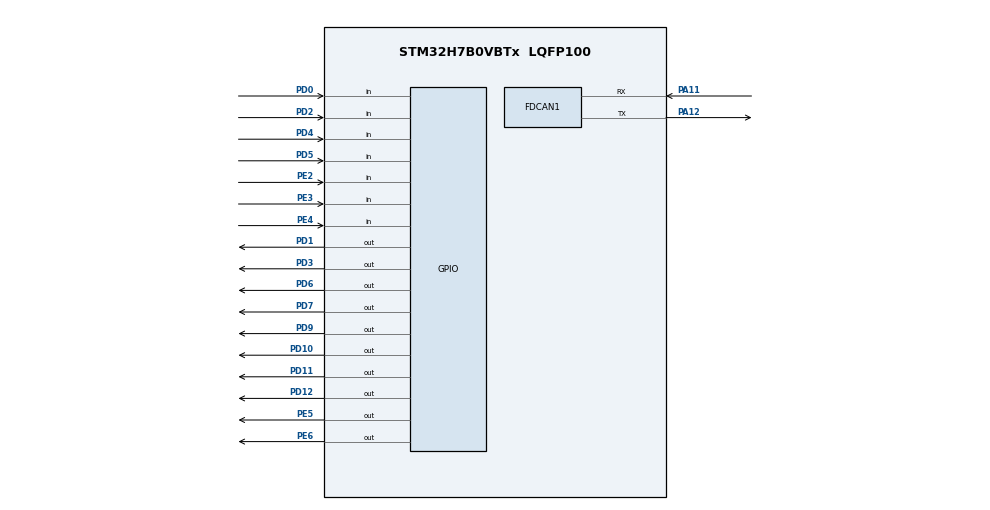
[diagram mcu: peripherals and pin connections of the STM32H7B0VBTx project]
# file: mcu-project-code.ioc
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FDCAN1.CalculateBaudRateNominal=533333
FDCAN1.CalculateTimeBitNominal=1875
FDCAN1.CalculateTimeQuantumNominal=375.0
Mcu.Family=STM32H7
Mcu.Name=STM32H7B0VBTx
Mcu.Package=LQFP100
NVIC.PriorityGroup=NVIC_PRIORITYGROUP_4
PA10.Signal=USART1_RX
PA11.Mode=FDCAN_Activate
PA11.Signal=FDCAN1_RX
PA12.Mode=FDCAN_Activate
PA12.Signal=FDCAN1_TX
PA13.Mode=JTAG_5_pins
PA13.Signal=DEBUG_JTMS-SWDIO
PA14.Mode=JTAG_5_pins
PA14.Signal=DEBUG_JTCK-SWCLK
PA15.Mode=JTAG_5_pins
PA15.Signal=DEBUG_JTDI
PA9.Signal=USART1_TX
PB13.Signal=SPI2_SCK
PB14.Signal=SPI2_MISO
PB15.Signal=SPI2_MOSI
PB3.Mode=JTAG_5_pins
PB3.Signal=DEBUG_JTDO-SWO
PB4.Mode=JTAG_5_pins
PB4.Signal=DEBUG_JTRST
PB6.Signal=I2C1_SCL
PB7.Signal=I2C1_SDA
PC10.Signal=USART3_TX
PC11.Signal=USART3_RX
PD0.Signal=GPIO_Input
PD1.Signal=GPIO_Output
PD10.Signal=GPIO_Output
PD11.Signal=GPIO_Output
PD12.Signal=GPIO_Output
PD2.Signal=GPIO_Input
PD3.Signal=GPIO_Output
PD4.Signal=GPIO_Input
PD5.Signal=GPIO_Input
PD6.Signal=GPIO_Output
PD7.Signal=GPIO_Output
PD9.Signal=GPIO_Output
PE2.Signal=GPIO_Input
PE3.Signal=GPIO_Input
PE4.Signal=GPIO_Input
PE5.Signal=GPIO_Output
PE6.Signal=GPIO_Output
ProjectManager.HeapSize=0x200
ProjectManager.StackSize=0x400
ProjectManager.TargetToolchain=STM32CubeIDE
RCC.ADCFreq_Value=129000000
RCC.APB1Freq_Value=32000000
RCC.APB2Freq_Value=32000000
RCC.APB3Freq_Value=32000000
RCC.APB4Freq_Value=32000000
RCC.CDPPRE=RCC_APB3_DIV2
RCC.CDPPRE1=RCC_APB1_DIV2
RCC.CDPPRE2=RCC_APB2_DIV2
RCC.CortexFreq_Value=64000000
RCC.DIVM1=4
RCC.DIVN1=8
RCC.DIVQ1=3
RCC.HCLKFreq_Value=64000000
RCC.PLLFRACN=0
RCC.SRDPPRE=RCC_APB4_DIV2
RCC.SYSCLKFreq_VALUE=64000000
RCC.USBFreq_Value=42666666.666666664
board=custom

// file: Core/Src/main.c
/* USER CODE BEGIN Header */
/**
  ******************************************************************************
  * @file           : main.c
  * @brief          : Main program body
  ******************************************************************************
  * @attention
  *
  * Copyright (c) 2026 STMicroelectronics.
  * All rights reserved.
  *
  * This software is licensed under terms that can be found in the LICENSE file
  * in the root directory of this software component.
  * If no LICENSE file comes with this software, it is provided AS-IS.
  *
  ******************************************************************************
  */
/* USER CODE END Header */
#include "main.h"

FDCAN_HandleTypeDef hfdcan1;

void SystemClock_Config(void);
static void MPU_Config(void);
static void MX_GPIO_Init(void);
static void MX_FDCAN1_Init(void);
static void UART_Init(void);
static void UART_Tx(void);
static void UART_Rx(void);

//CONOPS
static void Radio_Tx(int32_t data);
static int32_t Sensors_Rx(void);

int main(void)
{

  /* MPU Configuration--------------------------------------------------------*/
  MPU_Config();

  /* MCU Configuration--------------------------------------------------------*/

  /* Reset of all peripherals, Initializes the Flash interface and the Systick. */
  HAL_Init();

  /* Configure the system clock */
  SystemClock_Config();

  /* Initialize all configured peripherals */
  MX_GPIO_Init();
  MX_FDCAN1_Init();

  /* Infinite loop */
  /* USER CODE BEGIN WHILE */
  while (1)
  {

	  /*
	   * Wait for Sensors RX
	   * When Sensors Rx Radio Tx
	   * Win
	   */
    /* USER CODE END WHILE */
	  int32_t data = Sensors_Rx();
	  if (data) {
		  Radio_Tx(data);
	  } else {
		  continue;
	  }

  }
}

void SystemClock_Config(void)
{
  RCC_OscInitTypeDef RCC_OscInitStruct = {0};
  RCC_ClkInitTypeDef RCC_ClkInitStruct = {0};

  /*AXI clock gating */
  RCC->CKGAENR = 0xFFFFFFFF;

  /** Supply configuration update enable
  */
  HAL_PWREx_ConfigSupply(PWR_LDO_SUPPLY);

  /** Configure the main internal regulator output voltage
  */
  __HAL_PWR_VOLTAGESCALING_CONFIG(PWR_REGULATOR_VOLTAGE_SCALE3);

  while(!__HAL_PWR_GET_FLAG(PWR_FLAG_VOSRDY)) {}

  /** Initializes the RCC Oscillators according to the specified parameters
  * in the RCC_OscInitTypeDef structure.
  */
  RCC_OscInitStruct.OscillatorType = RCC_OSCILLATORTYPE_HSI;
  RCC_OscInitStruct.HSIState = RCC_HSI_DIV1;
  RCC_OscInitStruct.HSICalibrationValue = 64;
  RCC_OscInitStruct.PLL.PLLState = RCC_PLL_ON;
  RCC_OscInitStruct.PLL.PLLSource = RCC_PLLSOURCE_HSI;
  RCC_OscInitStruct.PLL.PLLM = 4;
  RCC_OscInitStruct.PLL.PLLN = 8;
  RCC_OscInitStruct.PLL.PLLP = 2;
  RCC_OscInitStruct.PLL.PLLQ = 3;
  RCC_OscInitStruct.PLL.PLLR = 2;
  RCC_OscInitStruct.PLL.PLLRGE = RCC_PLL1VCIRANGE_3;
  RCC_OscInitStruct.PLL.PLLVCOSEL = RCC_PLL1VCOWIDE;
  RCC_OscInitStruct.PLL.PLLFRACN = 0;
  if (HAL_RCC_OscConfig(&RCC_OscInitStruct) != HAL_OK)
  {
    Error_Handler();
  }

  /** Initializes the CPU, AHB and APB buses clocks
  */
  RCC_ClkInitStruct.ClockType = RCC_CLOCKTYPE_HCLK|RCC_CLOCKTYPE_SYSCLK
                              |RCC_CLOCKTYPE_PCLK1|RCC_CLOCKTYPE_PCLK2
                              |RCC_CLOCKTYPE_D3PCLK1|RCC_CLOCKTYPE_D1PCLK1;
  RCC_ClkInitStruct.SYSCLKSource = RCC_SYSCLKSOURCE_HSI;
  RCC_ClkInitStruct.SYSCLKDivider = RCC_SYSCLK_DIV1;
  RCC_ClkInitStruct.AHBCLKDivider = RCC_HCLK_DIV1;
  RCC_ClkInitStruct.APB3CLKDivider = RCC_APB3_DIV2;
  RCC_ClkInitStruct.APB1CLKDivider = RCC_APB1_DIV2;
  RCC_ClkInitStruct.APB2CLKDivider = RCC_APB2_DIV2;
  RCC_ClkInitStruct.APB4CLKDivider = RCC_APB4_DIV2;

  if (HAL_RCC_ClockConfig(&RCC_ClkInitStruct, FLASH_LATENCY_2) != HAL_OK)
  {
    Error_Handler();
  }
}

static void MX_FDCAN1_Init(void)
{

  hfdcan1.Instance = FDCAN1;
  hfdcan1.Init.FrameFormat = FDCAN_FRAME_CLASSIC;
  hfdcan1.Init.Mode = FDCAN_MODE_NORMAL;
  hfdcan1.Init.AutoRetransmission = DISABLE;
  hfdcan1.Init.TransmitPause = DISABLE;
  hfdcan1.Init.ProtocolException = DISABLE;
  hfdcan1.Init.NominalPrescaler = 16;
  hfdcan1.Init.NominalSyncJumpWidth = 1;
  hfdcan1.Init.NominalTimeSeg1 = 2;
  hfdcan1.Init.NominalTimeSeg2 = 2;
  hfdcan1.Init.DataPrescaler = 1;
  hfdcan1.Init.DataSyncJumpWidth = 1;
  hfdcan1.Init.DataTimeSeg1 = 1;
  hfdcan1.Init.DataTimeSeg2 = 1;
  hfdcan1.Init.MessageRAMOffset = 0;
  hfdcan1.Init.StdFiltersNbr = 0;
  hfdcan1.Init.ExtFiltersNbr = 0;
  hfdcan1.Init.RxFifo0ElmtsNbr = 0;
  hfdcan1.Init.RxFifo0ElmtSize = FDCAN_DATA_BYTES_8;
  hfdcan1.Init.RxFifo1ElmtsNbr = 0;
  hfdcan1.Init.RxFifo1ElmtSize = FDCAN_DATA_BYTES_8;
  hfdcan1.Init.RxBuffersNbr = 0;
  hfdcan1.Init.RxBufferSize = FDCAN_DATA_BYTES_8;
  hfdcan1.Init.TxEventsNbr = 0;
  hfdcan1.Init.TxBuffersNbr = 0;
  hfdcan1.Init.TxFifoQueueElmtsNbr = 0;
  hfdcan1.Init.TxFifoQueueMode = FDCAN_TX_FIFO_OPERATION;
  hfdcan1.Init.TxElmtSize = FDCAN_DATA_BYTES_8;
  if (HAL_FDCAN_Init(&hfdcan1) != HAL_OK)
  {
    Error_Handler();
  }

}

static void MX_GPIO_Init(void)
{
  GPIO_InitTypeDef GPIO_InitStruct = {0};

  /* GPIO Ports Clock Enable */
  __HAL_RCC_GPIOE_CLK_ENABLE();
  __HAL_RCC_GPIOB_CLK_ENABLE();
  __HAL_RCC_GPIOD_CLK_ENABLE();
  __HAL_RCC_GPIOA_CLK_ENABLE();
  __HAL_RCC_GPIOC_CLK_ENABLE();

  /*Configure GPIO pin Output Level */
  HAL_GPIO_WritePin(GPIOE, GPIO_PIN_5|GPIO_PIN_6, GPIO_PIN_RESET);

  /*Configure GPIO pin Output Level */
  HAL_GPIO_WritePin(GPIOD, GPIO_PIN_9|GPIO_PIN_10|GPIO_PIN_11|GPIO_PIN_12
                          |GPIO_PIN_1|GPIO_PIN_3|GPIO_PIN_6|GPIO_PIN_7, GPIO_PIN_RESET);

  /*Configure GPIO pins : PE2 PE3 PE4 */
  GPIO_InitStruct.Pin = GPIO_PIN_2|GPIO_PIN_3|GPIO_PIN_4;
  GPIO_InitStruct.Mode = GPIO_MODE_INPUT;
  GPIO_InitStruct.Pull = GPIO_NOPULL;
  HAL_GPIO_Init(GPIOE, &GPIO_InitStruct);

  /*Configure GPIO pins : PE5 PE6 */
  GPIO_InitStruct.Pin = GPIO_PIN_5|GPIO_PIN_6;
  GPIO_InitStruct.Mode = GPIO_MODE_OUTPUT_PP;
  GPIO_InitStruct.Pull = GPIO_NOPULL;
  GPIO_InitStruct.Speed = GPIO_SPEED_FREQ_LOW;
  HAL_GPIO_Init(GPIOE, &GPIO_InitStruct);

  /*Configure GPIO pins : PB13 PB14 PB15 */
  GPIO_InitStruct.Pin = GPIO_PIN_13|GPIO_PIN_14|GPIO_PIN_15;
  GPIO_InitStruct.Mode = GPIO_MODE_AF_PP;
  GPIO_InitStruct.Pull = GPIO_NOPULL;
  GPIO_InitStruct.Speed = GPIO_SPEED_FREQ_LOW;
  GPIO_InitStruct.Alternate = GPIO_AF5_SPI2;
  HAL_GPIO_Init(GPIOB, &GPIO_InitStruct);

  /*Configure GPIO pins : PD9 PD10 PD11 PD12
                           PD1 PD3 PD6 PD7 */
  GPIO_InitStruct.Pin = GPIO_PIN_9|GPIO_PIN_10|GPIO_PIN_11|GPIO_PIN_12
                          |GPIO_PIN_1|GPIO_PIN_3|GPIO_PIN_6|GPIO_PIN_7;
  GPIO_InitStruct.Mode = GPIO_MODE_OUTPUT_PP;
  GPIO_InitStruct.Pull = GPIO_NOPULL;
  GPIO_InitStruct.Speed = GPIO_SPEED_FREQ_LOW;
  HAL_GPIO_Init(GPIOD, &GPIO_InitStruct);

  /*Configure GPIO pins : PA9 PA10 */
  GPIO_InitStruct.Pin = GPIO_PIN_9|GPIO_PIN_10;
  GPIO_InitStruct.Mode = GPIO_MODE_AF_PP;
  GPIO_InitStruct.Pull = GPIO_NOPULL;
  GPIO_InitStruct.Speed = GPIO_SPEED_FREQ_LOW;
  GPIO_InitStruct.Alternate = GPIO_AF7_USART1;
  HAL_GPIO_Init(GPIOA, &GPIO_InitStruct);

  /*Configure GPIO pins : PC10 PC11 */
  GPIO_InitStruct.Pin = GPIO_PIN_10|GPIO_PIN_11;
  GPIO_InitStruct.Mode = GPIO_MODE_AF_PP;
  GPIO_InitStruct.Pull = GPIO_NOPULL;
  GPIO_InitStruct.Speed = GPIO_SPEED_FREQ_LOW;
  GPIO_InitStruct.Alternate = GPIO_AF7_USART3;
  HAL_GPIO_Init(GPIOC, &GPIO_InitStruct);

  /*Configure GPIO pins : PD0 PD2 PD4 PD5 */
  GPIO_InitStruct.Pin = GPIO_PIN_0|GPIO_PIN_2|GPIO_PIN_4|GPIO_PIN_5;
  GPIO_InitStruct.Mode = GPIO_MODE_INPUT;
  GPIO_InitStruct.Pull = GPIO_NOPULL;
  HAL_GPIO_Init(GPIOD, &GPIO_InitStruct);

  /*Configure GPIO pins : PB6 PB7 */
  GPIO_InitStruct.Pin = GPIO_PIN_6|GPIO_PIN_7;
  GPIO_InitStruct.Mode = GPIO_MODE_AF_OD;
  GPIO_InitStruct.Pull = GPIO_NOPULL;
  GPIO_InitStruct.Speed = GPIO_SPEED_FREQ_LOW;
  GPIO_InitStruct.Alternate = GPIO_AF4_I2C1;
  HAL_GPIO_Init(GPIOB, &GPIO_InitStruct);

}

/* MPU Configuration */

void MPU_Config(void)
{
  MPU_Region_InitTypeDef MPU_InitStruct = {0};

  /* Disables the MPU */
  HAL_MPU_Disable();

  /** Initializes and configures the Region and the memory to be protected
  */
  MPU_InitStruct.Enable = MPU_REGION_ENABLE;
  MPU_InitStruct.Number = MPU_REGION_NUMBER0;
  MPU_InitStruct.BaseAddress = 0x0;
  MPU_InitStruct.Size = MPU_REGION_SIZE_4GB;
  MPU_InitStruct.SubRegionDisable = 0x87;
  MPU_InitStruct.TypeExtField = MPU_TEX_LEVEL0;
  MPU_InitStruct.AccessPermission = MPU_REGION_NO_ACCESS;
  MPU_InitStruct.DisableExec = MPU_INSTRUCTION_ACCESS_DISABLE;
  MPU_InitStruct.IsShareable = MPU_ACCESS_SHAREABLE;
  MPU_InitStruct.IsCacheable = MPU_ACCESS_NOT_CACHEABLE;
  MPU_InitStruct.IsBufferable = MPU_ACCESS_NOT_BUFFERABLE;

  HAL_MPU_ConfigRegion(&MPU_InitStruct);
  /* Enables the MPU */
  HAL_MPU_Enable(MPU_PRIVILEGED_DEFAULT);

}

static void Radio_Tx(int32_t data){

}
static int32_t Sensors_Rx(void){
	return 0;
}

static void UART_Init(void){

}
static void UART_Tx(void){

}
static void UART_Rx(void){

}

void Error_Handler(void)
{
  __disable_irq();
  while (1)
  {
  }
}
